# STM32WB05 register map
File version: 1.0
CPU: CM0+ r0p0, little endian, MPU, no FPU, 2 interrupt priority bits
Registers are 32-bit, read-write, reset 0x0 unless marked. A register's access mark holds for its fields unless they carry their own. Offsets are from the block's base; [hi:lo] are bit positions; 'fields as' and 'values as' point back to an identical list.

## RTC
Base 0x40004000
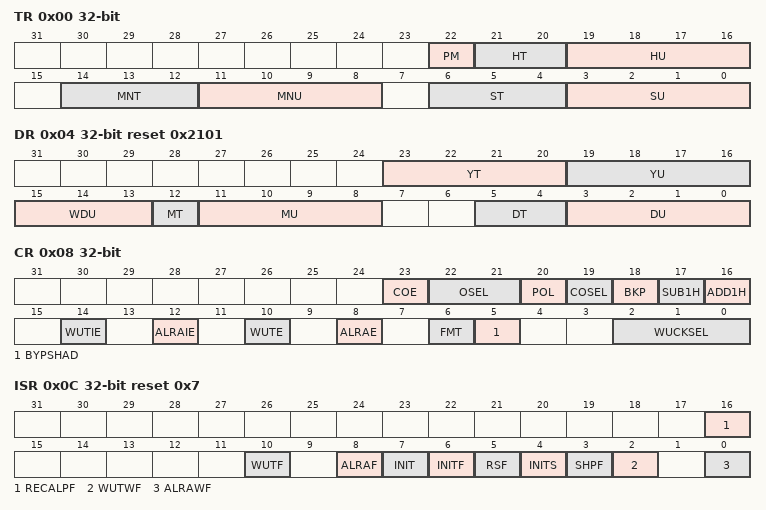
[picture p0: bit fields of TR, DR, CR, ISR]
0x00 TR — RTC_TR register
  [22] PM — AM/PM notation. 0: AM or 24-hour format 1: PM
  [21:20] HT — Hour tens in BCD format.
  [19:16] HU — Hour units in BCD format.
  [14:12] MNT — Minute tens in BCD format.
  [11:8] MNU — Minute units in BCD format.
  [6:4] ST — Second tens in BCD format.
  [3:0] SU — Second units in BCD format.
0x04 DR reset 0x2101 — RTC_DR register
  [23:20] YT — Year tens in BCD format.
  [19:16] YU — Year units in BCD format.
  [15:13] WDU — Week day units 000: forbidden 001: Monday 010: Tuesday 011: Wednesday 100: Thursday 101: Friday 110: Saturday 111: Sunday
  [12] MT — Month tens in BCD format.
  [11:8] MU — Month units in BCD format.
  [5:4] DT — Date tens in BCD format.
  [3:0] DU — Date units in BCD format.
0x08 CR — RTC_CR register
  [23] COE — Calibration output enable This bit enables the RTC_CALIB output 0: Calibration output disabled 1: Calibration output enabled
  [22:21] OSEL — Output selection These bits are used to select the flag to be routed to RTC_ALARM output 00: Output disabled 01: Alarm A output enabled 10: Reserved 11: Wakeup output enabled
  [20] POL — Output polarity This bit is used to configure the polarity of RTC_ALARM output 0: The pin is high when ALRAF/WUTF is asserted (depending on OSEL[1:0]) 1: The pin is low when ALRAF/WUTF is asserted (depending on OSEL[1:0]).
  [19] COSEL — Calibration output selection When COE=1, this bit selects which signal is output on RTC_CALIB. 0: Calibration output is 512 Hz 1: Calibration output is 1 Hz These frequencies are valid for RTCCLK at 32.768 kHz and prescalers at their default values (PREDIV_A=127 and PREDIV_S=255).
  [18] BKP — Backup This bit can be written by the user to memorize whether the daylight saving time change has been performed or not.
  [17] SUB1H wo — Subtract 1 hour (winter time change) When this bit is set outside initialization mode, 1 hour is subtracted to the calendar time if the current hour is not 0. This bit is always read as 0. Setting this bit has no effect when current hour is 0. 0: No effect 1: Subtracts 1 hour to the current time. This can be used for winter time change.
  [16] ADD1H wo — Add 1 hour (summer time change) When this bit is set outside initialization mode, 1 hour is added to the calendar time. This bit is always read as 0. 0: No effect 1: Adds 1 hour to the current time. This can be used for summer time change
  [14] WUTIE — Wakeup timer interrupt enable 0: Wakeup timer interrupt disabled 1: Wakeup timer interrupt enabled
  [12] ALRAIE — Alarm A interrupt enable 0: Alarm A interrupt disabled 1: Alarm A interrupt enabled
  [10] WUTE — Wakeup timer enable 0: Wakeup timer disabled 1: Wakeup timer enabled
  [8] ALRAE — Alarm A enable 0: Alarm A disabled 1: Alarm A enabled
  [6] FMT — Hour format
  [5] BYPSHAD — Bypass the shadow registers 0: Calendar values (when reading from RTC_SSR, RTC_TR, and RTC_DR) are taken from the shadow registers, which are updated once every two RTCCLK cycles. 1: Calendar values (when reading from RTC_SSR, RTC_TR, and RTC_DR) are taken directly from the calendar counters.
  [2:0] WUCKSEL — Wakeup clock selection 000: RTC/16 clock is selected 001: RTC/8 clock is selected 010: RTC/4 clock is selected 011: RTC/2 clock is selected 10x: ck_spre (usually 1 Hz) clock is selected 11x: ck_spre (usually 1 Hz) clock is selected and 216 is added to the WUT counter value
0x0C ISR reset 0x7 — RTC_ISR register
  [16] RECALPF — Recalibration pending Flag The RECALPF status flag is automatically set to 1' when software writes to the RTC_CALR register, indicating that the RTC_CALR register is blocked. When the new calibration settings are taken into account, this bit returns to 0'.
  [10] WUTF — Wakeup timer flag This flag is set by hardware when the wakeup auto-reload counter reaches 0. This flag is cleared by software by writing 0. This flag must be cleared by software at least 1.5 RTCCLK periods before WUTF is set to 1 again.
  [8] ALRAF — Alarm A flag This flag is set by hardware when the time/date registers (RTC_TR and RTC_DR) match the Alarm A register (RTC_ALRMAR). This flag is cleared by software by writing 0.
  [7] INIT — Initialization mode 0: Free running mode 1: Initialization mode used to program time and date register (RTC_TR and RTC_DR), and prescaler register (RTC_PRER). Counters are stopped and start counting from the new value when INIT is reset.
  [6] INITF — Initialization flag When this bit is set to 1, the RTC is in initialization state, and the time, date and prescaler registers can be updated. 0: Calendar registers update is not allowed 1: Calendar registers update is allowed.
  [5] RSF — Registers synchronization flag This bit is set by hardware each time the calendar registers are copied into the shadow registers (RTC_SSRx, RTC_TRx and RTC_DRx). This bit is cleared by hardware in initialization mode, while a shift operation is pending (SHPF=1), or when in bypass shadow regsiter mode (BYPSHAD=1). This bit can also be cleared by software. It is cleared either by software or by hardware in initialization mode. 0: Calendar shadow registers not yet synchronized 1: Calendar shadow registers synchronized.
  [4] INITS — Initialization status flag This bit is set by hardware when the calendar year field is different from 0 (power-on reset state). 0: Calendar has not been initialized 1: Calendar has been initialized
  [3] SHPF — Shift operation pending 0: No shift operation is pending 1: A shift operation is pending This flag is set by hardware as soon as a shift operation is initiated by a write to the RTC_SHIFTR register. It is cleared by hardware when the corresponding shift operation has been executed. Writing to the SHPF bit has no effect.
  [2] WUTWF — Wakeup timer write flag This bit is set by hardware when the wakeup timer values can be changed, after the WUTE bit has been set to 0 in RTC_CR. 0: Wakeup timer configuration update not allowed 1: Wakeup timer configuration update allowed.
  [0] ALRAWF — Alarm A write flag This bit is set by hardware when Alarm A values can be changed, after the ALRAE bit has been set to 0 in RTC_CR. It is cleared by hardware in initialization mode. 0: Alarm A update not allowed 1: Alarm A update allowed.
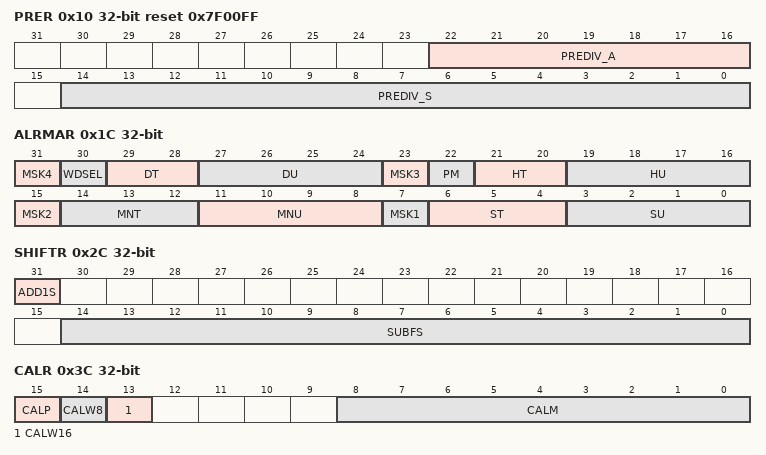
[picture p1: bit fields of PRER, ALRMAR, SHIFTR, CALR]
0x10 PRER reset 0x7F00FF — RTC_PRER register
  [22:16] PREDIV_A — Asynchronous prescaler factor This is the asynchronous division factor: ck_apre frequency = RTCCLK frequency/(PREDIV_A+1)
  [14:0] PREDIV_S — Synchronous prescaler factor This is the synchronous division factor: ck_spre frequency = ck_apre frequency/(PREDIV_S+1)
0x14 WUTR reset 0xFFFF — RTC_WUTR register
  [15:0] WUT — Wakeup auto-reload value bits When the wakeup timer is enabled (WUTE set to 1), the WUTF flag is set every (WUT[15:0] + 1) ck_wut cycles. The ck_wut period is selected through WUCKSEL[2:0] bits of the RTC_CR register When WUCKSEL[2] = 1, the wakeup timer becomes 17-bits and WUCKSEL[1] effectively becomes WUT[16] the most-significant bit to be reloaded into the timer. The first assertion of WUTF occurs (WUT+1) ck_wut cycles after WUTE is set. Setting WUT[15:0] to 0x0000 with WUCKSEL[2:0] =011 (RTCCLK/2) is forbidden.
0x1C ALRMAR — RTC_ALRMAR register
  [31] MSK4 — Alarm A date mask 0: Alarm A set if the date/day match 1: Date/day don't care in Alarm A comparison
  [30] WDSEL — Week day selection 0: DU[3:0] represents the date units 1: DU[3:0] represents the week day. DT[1:0] is don't care.
  [29:28] DT — Date tens in BCD format.
  [27:24] DU — Date units or day in BCD format.
  [23] MSK3 — Alarm A hours mask 0: Alarm A set if the hours match 1: Hours don't care in Alarm A comparison
  [22] PM — AM/PM notation 0: AM or 24-hour format 1: PM
  [21:20] HT — Hour tens in BCD format.
  [19:16] HU — Hour units in BCD format.
  [15] MSK2 — Alarm A minutes mask 0: Alarm A set if the minutes match 1: Minutes don't care in Alarm A comparison
  [14:12] MNT — Minute tens in BCD format.
  [11:8] MNU — Minute units in BCD format.
  [7] MSK1 — Alarm A seconds mask 0: Alarm A set if the seconds match 1: Seconds don't care in Alarm A comparison
  [6:4] ST — Second tens in BCD format.
  [3:0] SU — Second units in BCD format.
0x24 WPR — RTC_WPR register
  [7:0] KEY wo — Write protection key This byte is written by software. Reading this byte always returns 0x00
0x28 SSR ro — RTC_SSR register
  [15:0] SS — Sub second value SS[15:0] is the value in the synchronous prescaler's counter. The fraction of a second is given by the formula below: Second fraction = ( PREDIV_S - SS ) / ( PREDIV_S + 1 )
0x2C SHIFTR — RTC_SHIFTR register
  [31] ADD1S wo — Add one second 0: No effect 1: Add one second to the clock/calendar This bit is write only and is always read as zero. Writing to this bit has no effect when a shift operation is pending (when SHPF=1, in RTC_ISR). This function is intended to be used with SUBFS (see description below) in order to effectively add a fraction of a second to the clock in an atomic operation.
  [14:0] SUBFS wo — Subtract a fraction of a second These bits are write only and is always read as zero. Writing to this bit has no effect when a shift operation is pending (when SHPF=1, in RTC_ISR). The value which is written to SUBFS is added to the synchronous prescaler's counter. Since this counter counts down, this operation effectively subtracts from (delays) the clock by: Delay (seconds) = SUBFS / ( PREDIV_S + 1 ) A fraction of a second can effectively be added to the clock (advancing the clock) when the ADD1S function is used in conjunction with SUBFS, effectively advancing the clock by : Advance (seconds) = ( 1 - ( SUBFS / ( PREDIV_S + 1 ) ) ) .
0x3C CALR — RTC_CALR register
  [15] CALP — Increase frequency of RTC by 488.5 ppm 0: No RTCCLK pulses are added. 1: One RTCCLK pulse is effectively inserted every 211 pulses (frequency incresed by 488.5 ppm). This feature is intended to be used in conjunction with CALM, which lowers the frequency of the calendar with a fine resolution. if the input frequency is 32768 Hz, the number of RTCCLK pulses added during a 32-second window is calculated as follows: (512 * CALP) - CALM.
  [14] CALW8 — Use an 8-second calibration cycle period When CALW8 is set to 1' , the 8-second calibration cycle period is selected. Note: CALM[1:0] are stucked at '00' when CALW8='1'.
  [13] CALW16 — Use a 16-second calibration cycle period When CALW16 is set to 1' , the 16-second calibration cycle period is selected.This bit must not be set to 1' if CALW8=1. Note: CALM[0] is stucked at 0' when CALW16='1'.
  [8:0] CALM — Calibration minus The frequency of the calendar is reduced by masking CALM out of 220 RTCCLK pulses (32 seconds if the input frequency is 32768 Hz). This decreases the frequency of the calendar with a resolution of 0.9537 ppm. To increase the frequency of the calendar, this feature should be used in conjunction with CALP.
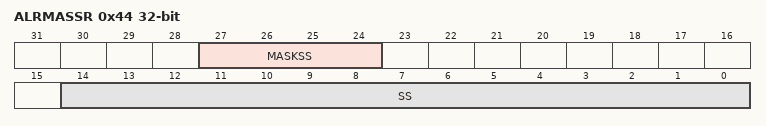
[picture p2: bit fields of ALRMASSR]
0x44 ALRMASSR — RTC_ALRMASSR register
  [27:24] MASKSS — Mask the most-significant bits starting at this bit 0: No comparison on sub seconds for Alarm A. The alarm is set when the seconds unit is incremented (assuming that the rest of the fields match). 1: SS[14:1] are don't care in Alarm A comparison. Only SS[0] is compared. 2: SS[14:2] are don't care in Alarm A comparison. Only SS[1:0] are compared. 3: SS[14:3] are don't care in Alarm A comparison. Only SS[2:0] are compared. ... 12: SS[14:12] are don't care in Alarm A comparison. SS[11:0] are compared. 13: SS[14:13] are don't care in Alarm A comparison. SS[12:0] are compared. 14: SS[14] is don't care in Alarm A comparison. SS[13:0] are compared. 15: All 15 SS bits are compared and must match to activate alarm. The overflow bits of the synchronous counter (bits 15) is never compared. This bit can be different from 0 only after a shift operation.
  [14:0] SS — Sub seconds value This value is compared with the contents of the synchronous prescaler's counter to determine if Alarm A is to be activated. Only bits 0 up MASKSS-1 are compared.
0x50 BKP0R — RTC_BKP0R register
  [31:0] BKP — The application can write or read data to and from these registers. They are powered-on by VDD12o so they are retained during DEEPSTOP mode. The application can write or read data to and from these registers. This register is reset on PORESETn only.
0x54 BKP1R — RTC_BKP1R register
  fields as BKP0R
